# dsPIC33FJ64GS606 register map
Vendor: Microchip; Series: dsPIC33FJ64GS; File version: 1.4.228
Registers are 16-bit, read-write, no defined reset value unless marked. A register's access mark holds for its fields unless they carry their own. Offsets are from the block's base; [hi:lo] are bit positions; {n}, {i} and the like mark numbered series.

## GPIOF — GPIOF peripheral registers
Base 0x000002E8
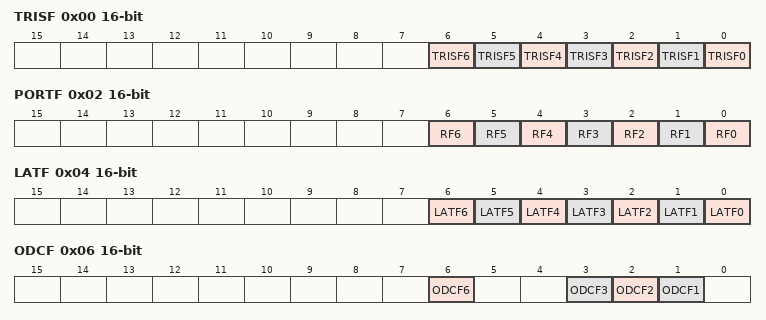
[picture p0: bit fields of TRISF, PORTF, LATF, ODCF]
0x00 TRISF
  [n] TRISF{n} (n=0..6) — TRISF field TRISF{n}
0x02 PORTF
  [n] RF{n} (n=0..6) — PORTF field RF{n}
0x04 LATF
  [n] LATF{n} (n=0..6) — LATF field LATF{n}
0x06 ODCF
  [6] ODCF6 — ODCF field ODCF6
  [3] ODCF3 — ODCF field ODCF3
  [2] ODCF2 — ODCF field ODCF2
  [1] ODCF1 — ODCF field ODCF1

## GPIOG — GPIOG peripheral registers
Base 0x000002F0
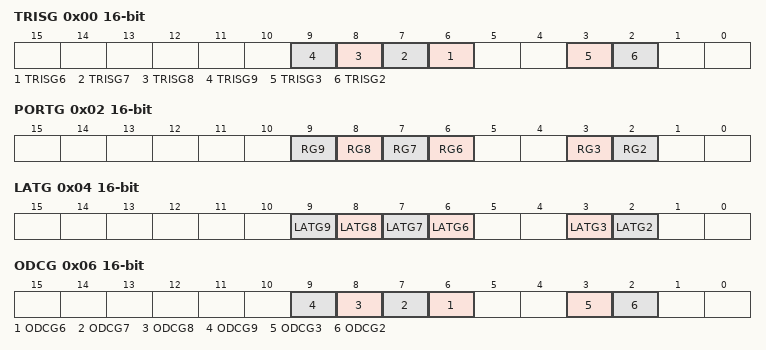
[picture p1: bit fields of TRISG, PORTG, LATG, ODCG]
0x00 TRISG
  [n] TRISG{n} (n=6..9) — TRISG field TRISG{n}
  [3] TRISG3 — TRISG field TRISG3
  [2] TRISG2 — TRISG field TRISG2
0x02 PORTG
  [n] RG{n} (n=6..9) — PORTG field RG{n}
  [3] RG3 — PORTG field RG3
  [2] RG2 — PORTG field RG2
0x04 LATG
  [n] LATG{n} (n=6..9) — LATG field LATG{n}
  [3] LATG3 — LATG field LATG3
  [2] LATG2 — LATG field LATG2
0x06 ODCG
  [n] ODCG{n} (n=6..9) — ODCG field ODCG{n}
  [3] ODCG3 — ODCG field ODCG3
  [2] ODCG2 — ODCG field ODCG2

## ADC — ADC peripheral registers
Base 0x00000300
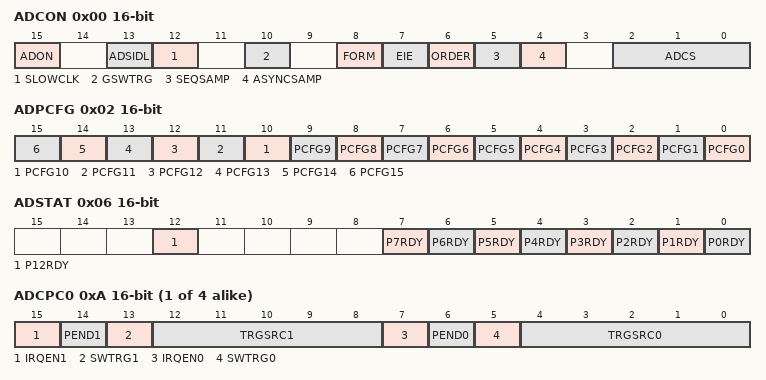
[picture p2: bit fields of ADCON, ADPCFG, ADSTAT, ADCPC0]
0x00 ADCON
  [15] ADON — ADC module operating mode bit
  [13] ADSIDL — ADC stop in Idle mode bit
  [12] SLOWCLK — Enable the slow clock divider bit
  [10] GSWTRG — Global software trigger bit
  [8] FORM — Data output format bit
  [7] EIE — Early interrupt enable bit
  [6] ORDER — Conversion order bit
  [5] SEQSAMP — Sequential sample-and-hold sampling enable bit
  [4] ASYNCSAMP — Asynchronous dedicated sample-and-hold sampling enable bit
  [2:0] ADCS — Analog-to-digital conversion clock divider select bits
0x02 ADPCFG
  [n] PCFG{n} (n=0..15) — ADPCFG field PCFG{n}
0x06 ADSTAT
  [12] P12RDY — ADSTAT field P12RDY
  [n] P{n}RDY (n=0..7) — ADSTAT field P{n}RDY
0x08 ADBASE
  [15:0] ADBASE — ADBASE register value
{0xA+2i} ADCPC{i} (i=0..3)
  [15] IRQEN{2i+1} — ADCPC{i} field IRQEN{2i+1}
  [14] PEND{2i+1} — ADCPC{i} field PEND{2i+1}
  [13] SWTRG{2i+1} — ADCPC{i} field SWTRG{2i+1}
  [12:8] TRGSRC{2i+1} — ADCPC{i} field TRGSRC{2i+1}
  [7] IRQEN{2i} — ADCPC{i} field IRQEN{2i}
  [6] PEND{2i} — ADCPC{i} field PEND{2i}
  [5] SWTRG{2i} — ADCPC{i} field SWTRG{2i}
  [4:0] TRGSRC{2i} — ADCPC{i} field TRGSRC{2i}
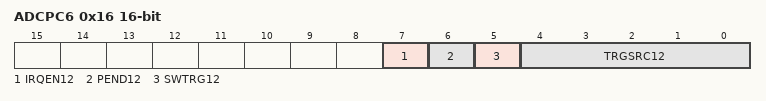
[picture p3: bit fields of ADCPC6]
0x16 ADCPC6
  [7] IRQEN12 — ADCPC6 field IRQEN12
  [6] PEND12 — ADCPC6 field PEND12
  [5] SWTRG12 — ADCPC6 field SWTRG12
  [4:0] TRGSRC12 — ADCPC6 field TRGSRC12
{0x40+2i} ADCBUF{i} (i=0..15)
  [15:0] ADCBUF{i} — ADCBUF{i} register value
0x70 ADCBUF24
  [15:0] ADCBUF24 — ADCBUF24 register value
0x72 ADCBUF25
  [15:0] ADCBUF25 — ADCBUF25 register value

## DMA0 — DMA0 peripheral registers
Base 0x00000380
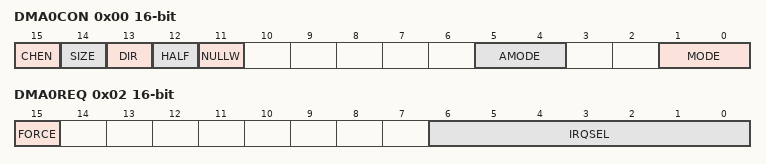
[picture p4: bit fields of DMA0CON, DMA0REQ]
0x00 DMA0CON
  [15] CHEN — DMA0CON field CHEN
  [14] SIZE — DMA0CON field SIZE
  [13] DIR — DMA0CON field DIR
  [12] HALF — DMA0CON field HALF
  [11] NULLW — DMA0CON field NULLW
  [5:4] AMODE — DMA0CON field AMODE
  [1:0] MODE — DMA0CON field MODE
0x02 DMA0REQ
  [15] FORCE — DMA0REQ field FORCE
  [6:0] IRQSEL — DMA0REQ field IRQSEL
0x04 DMA0STA
  [15:0] DMA0STA — DMA0STA register value
0x06 DMA0STB
  [15:0] DMA0STB — DMA0STB register value
0x08 DMA0PAD
  [15:0] DMA0PAD — DMA0PAD register value
0x0A DMA0CNT
  [15:0] DMA0CNT — DMA0CNT register value

## DMA1 — DMA1 peripheral registers
Base 0x0000038C
Registers as DMA0 (with DMA0 read as DMA1).

## DMA2 — DMA2 peripheral registers
Base 0x00000398
Registers as DMA0 (with DMA0 read as DMA2).

## DMA3 — DMA3 peripheral registers
Base 0x000003A4
Registers as DMA0 (with DMA0 read as DMA3).

## DMA — DMA peripheral registers
Base 0x000003E0
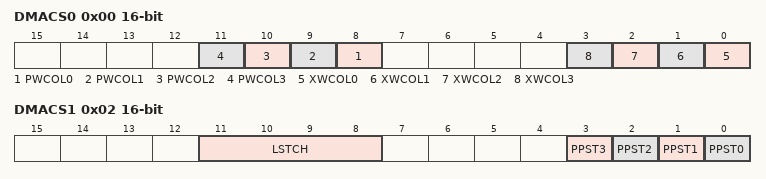
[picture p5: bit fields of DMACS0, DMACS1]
0x00 DMACS0
  [n+8] PWCOL{n} (n=0..3) — DMACS0 field PWCOL{n}
  [n] XWCOL{n} (n=0..3) — DMACS0 field XWCOL{n}
0x02 DMACS1
  [11:8] LSTCH — DMACS1 field LSTCH
  [n] PPST{n} (n=0..3) — DMACS1 field PPST{n}
0x04 DSADR
  [15:0] DSADR — DSADR register value
